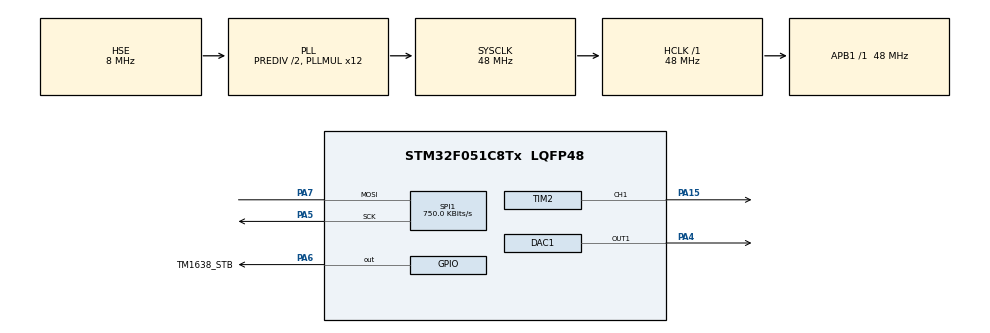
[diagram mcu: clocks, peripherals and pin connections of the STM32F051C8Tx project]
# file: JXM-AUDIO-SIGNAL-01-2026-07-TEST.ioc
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ADC.ContinuousConvMode=ENABLE
ADC.DMAContinuousRequests=ENABLE
ADC.EOCSelection=ADC_EOC_SEQ_CONV
ADC.SamplingTime=ADC_SAMPLETIME_239CYCLES_5
DAC1.DAC_OutputBuffer=DAC_OUTPUTBUFFER_ENABLE
DAC1.DAC_Trigger=DAC_TRIGGER_T6_TRGO
Dma.ADC.0.Direction=DMA_PERIPH_TO_MEMORY
Dma.ADC.0.Instance=DMA1_Channel1
Dma.ADC.0.MemDataAlignment=DMA_MDATAALIGN_HALFWORD
Dma.ADC.0.MemInc=DMA_MINC_ENABLE
Dma.ADC.0.Mode=DMA_CIRCULAR
Dma.ADC.0.PeriphDataAlignment=DMA_PDATAALIGN_HALFWORD
Dma.ADC.0.PeriphInc=DMA_PINC_DISABLE
Dma.ADC.0.Priority=DMA_PRIORITY_LOW
Dma.DAC1_CH1.1.Direction=DMA_MEMORY_TO_PERIPH
Dma.DAC1_CH1.1.Instance=DMA1_Channel3
Dma.DAC1_CH1.1.MemDataAlignment=DMA_MDATAALIGN_HALFWORD
Dma.DAC1_CH1.1.MemInc=DMA_MINC_ENABLE
Dma.DAC1_CH1.1.Mode=DMA_CIRCULAR
Dma.DAC1_CH1.1.PeriphDataAlignment=DMA_PDATAALIGN_HALFWORD
Dma.DAC1_CH1.1.PeriphInc=DMA_PINC_DISABLE
Dma.DAC1_CH1.1.Priority=DMA_PRIORITY_HIGH
Dma.Request0=ADC
Dma.Request1=DAC1_CH1
Mcu.Family=STM32F0
Mcu.Name=STM32F051C8Tx
Mcu.Package=LQFP48
NVIC.DMA1_Channel2_3_IRQn=true\:1\:0\:true\:false\:true\:true\:true\:true
PA13.Mode=Serial_Wire
PA13.Signal=SYS_SWDIO
PA14.Mode=Serial_Wire
PA14.Signal=SYS_SWCLK
PA15.GPIO_Speed=GPIO_SPEED_FREQ_HIGH
PA15.Signal=S_TIM2_CH1_ETR
PA2.Signal=USART2_TX
PA3.Signal=USART2_RX
PA4.Signal=COMP_DAC11_group
PA5.Mode=Simplex_Bidirectional_Master
PA5.Signal=SPI1_SCK
PA6.GPIO_Label=TM1638_STB
PA6.GPIO_Speed=GPIO_SPEED_FREQ_HIGH
PA6.PinState=GPIO_PIN_SET
PA6.Signal=GPIO_Output
PA7.GPIO_PuPd=GPIO_PULLUP
PA7.Mode=Simplex_Bidirectional_Master
PA7.Signal=SPI1_MOSI
PC14-OSC32_IN.Signal=RCC_OSC32_IN
PC15-OSC32_OUT.Signal=RCC_OSC32_OUT
PF0-OSC_IN.Mode=HSE-External-Oscillator
PF0-OSC_IN.Signal=RCC_OSC_IN
PF1-OSC_OUT.Mode=HSE-External-Oscillator
PF1-OSC_OUT.Signal=RCC_OSC_OUT
ProjectManager.HeapSize=0x200
ProjectManager.StackSize=0x400
ProjectManager.TargetToolchain=CMake
RCC.AHBFreq_Value=48000000
RCC.APB1Freq_Value=48000000
RCC.APB1TimFreq_Value=48000000
RCC.HCLKFreq_Value=48000000
RCC.PLLDivider=RCC_PREDIV_DIV2
RCC.PLLMUL=RCC_PLL_MUL12
RCC.PLLSourceVirtual=RCC_PLLSOURCE_HSE
RCC.SYSCLKFreq_VALUE=48000000
RCC.SYSCLKSource=RCC_SYSCLKSOURCE_PLLCLK
SH.COMP_DAC11_group.0=DAC1_OUT1,DAC_OUT1
SH.S_TIM2_CH1_ETR.0=TIM2_CH1,PWM Generation1 CH1
SPI1.BaudRatePrescaler=SPI_BAUDRATEPRESCALER_64
SPI1.CLKPhase=SPI_PHASE_2EDGE
SPI1.CLKPolarity=SPI_POLARITY_HIGH
SPI1.CalculateBaudRate=750.0 KBits/s
SPI1.DataSize=SPI_DATASIZE_8BIT
SPI1.Direction=SPI_DIRECTION_1LINE
SPI1.FirstBit=SPI_FIRSTBIT_LSB
SPI1.Mode=SPI_MODE_MASTER
SPI1.VirtualType=VM_MASTER
STMicroelectronics.X-CUBE-ALGOBUILD.1.5.0.LibraryCcDSPOoLibraryJjDSPOoLibrary=true
TIM2.AutoReloadPreload=TIM_AUTORELOAD_PRELOAD_ENABLE
TIM2.Channel-PWM\ Generation1\ CH1=TIM_CHANNEL_1
TIM2.CounterMode=TIM_COUNTERMODE_UP
TIM2.OC1Preload_PWM=ENABLE
TIM2.OCFastMode_PWM-PWM\ Generation1\ CH1=TIM_OCFAST_ENABLE
TIM2.Period=3300 - 1
TIM2.Pulse-PWM\ Generation1\ CH1=1500 - 1
TIM6.Period=47
TIM6.TIM_MasterOutputTrigger=TIM_TRGO_UPDATE
VP_ADC_TempSens_Input.Mode=IN-TempSens
VP_ADC_Vbat_Input.Mode=IN-Vbat
VP_ADC_Vref_Input.Mode=IN-Vrefint
VP_STMicroelectronics.X-CUBE-ALGOBUILD_VS_DSPOoLibraryJjLibrary_1.5.0_1.5.0.Mode=DSPOoLibraryJjLibrary
VP_TIM2_VS_ClockSourceINT.Mode=Internal
VP_TIM6_VS_ClockSourceINT.Mode=Enable_Timer
board=custom

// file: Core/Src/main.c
/* USER CODE BEGIN Header */
/**
  ******************************************************************************
  * @file           : main.c
  * @brief          : Main program body
  ******************************************************************************
  * @attention
  *
  * Copyright (c) 2026 STMicroelectronics.
  * All rights reserved.
  *
  * This software is licensed under terms that can be found in the LICENSE file
  * in the root directory of this software component.
  * If no LICENSE file comes with this software, it is provided AS-IS.
  *
  ******************************************************************************
  */
/* USER CODE END Header */
#include "main.h"
#include "adc.h"
#include "dac.h"
#include "dma.h"
#include "spi.h"
#include "tim.h"
#include "gpio.h"

/* USER CODE BEGIN Includes */
#include "MyCode.h"

/* USER CODE END Includes */

void SystemClock_Config(void);

int main(void)
{

  /* MCU Configuration--------------------------------------------------------*/

  /* Reset of all peripherals, Initializes the Flash interface and the Systick. */
  HAL_Init();

  /* Configure the system clock */
  SystemClock_Config();

  /* Initialize all configured peripherals */
  MX_GPIO_Init();
  MX_DMA_Init();
  MX_ADC_Init();
  MX_DAC1_Init();
  MX_SPI1_Init();
  MX_TIM6_Init();
  MX_TIM2_Init();
  /* USER CODE BEGIN 2 */

  Setup();

  /* USER CODE END 2 */

  /* Infinite loop */
  /* USER CODE BEGIN WHILE */
  while (1)
  {

    Loop();

    /* USER CODE END WHILE */

  }
}

void SystemClock_Config(void)
{
  RCC_OscInitTypeDef RCC_OscInitStruct = {0};
  RCC_ClkInitTypeDef RCC_ClkInitStruct = {0};

  /** Initializes the RCC Oscillators according to the specified parameters
  * in the RCC_OscInitTypeDef structure.
  */
  RCC_OscInitStruct.OscillatorType = RCC_OSCILLATORTYPE_HSI14|RCC_OSCILLATORTYPE_HSE;
  RCC_OscInitStruct.HSEState = RCC_HSE_ON;
  RCC_OscInitStruct.HSI14State = RCC_HSI14_ON;
  RCC_OscInitStruct.HSI14CalibrationValue = 16;
  RCC_OscInitStruct.PLL.PLLState = RCC_PLL_ON;
  RCC_OscInitStruct.PLL.PLLSource = RCC_PLLSOURCE_HSE;
  RCC_OscInitStruct.PLL.PLLMUL = RCC_PLL_MUL12;
  RCC_OscInitStruct.PLL.PREDIV = RCC_PREDIV_DIV2;
  if (HAL_RCC_OscConfig(&RCC_OscInitStruct) != HAL_OK)
  {
    Error_Handler();
  }

  /** Initializes the CPU, AHB and APB buses clocks
  */
  RCC_ClkInitStruct.ClockType = RCC_CLOCKTYPE_HCLK|RCC_CLOCKTYPE_SYSCLK
                              |RCC_CLOCKTYPE_PCLK1;
  RCC_ClkInitStruct.SYSCLKSource = RCC_SYSCLKSOURCE_PLLCLK;
  RCC_ClkInitStruct.AHBCLKDivider = RCC_SYSCLK_DIV1;
  RCC_ClkInitStruct.APB1CLKDivider = RCC_HCLK_DIV1;

  if (HAL_RCC_ClockConfig(&RCC_ClkInitStruct, FLASH_LATENCY_1) != HAL_OK)
  {
    Error_Handler();
  }
}

void Error_Handler(void)
{
  __disable_irq();
  while (1)
  {
  }
}
